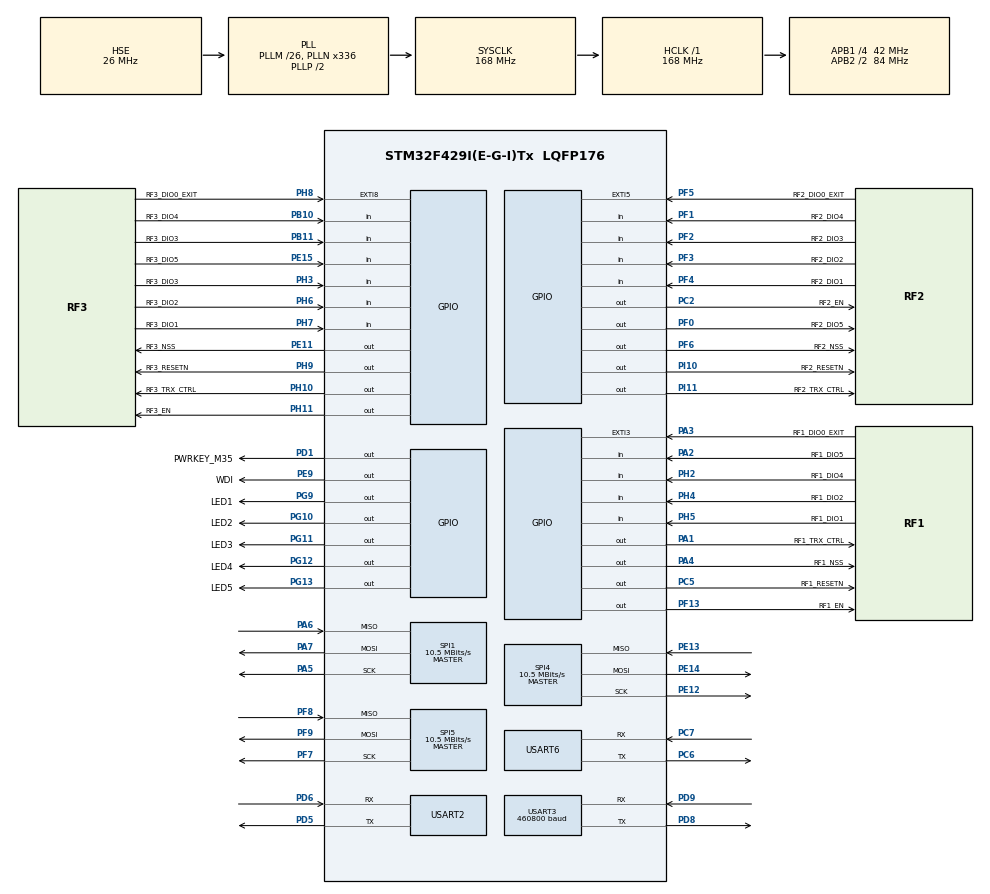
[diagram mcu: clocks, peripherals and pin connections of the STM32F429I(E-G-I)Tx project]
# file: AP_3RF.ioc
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Dma.Request0=USART3_RX
Dma.Request1=USART3_TX
Dma.Request2=USART6_RX
Dma.Request3=USART6_TX
Dma.Request4=USART2_RX
Dma.Request5=USART2_TX
Dma.USART2_RX.4.Direction=DMA_PERIPH_TO_MEMORY
Dma.USART2_RX.4.FIFOMode=DMA_FIFOMODE_DISABLE
Dma.USART2_RX.4.Instance=DMA1_Stream5
Dma.USART2_RX.4.MemDataAlignment=DMA_MDATAALIGN_BYTE
Dma.USART2_RX.4.MemInc=DMA_MINC_ENABLE
Dma.USART2_RX.4.Mode=DMA_NORMAL
Dma.USART2_RX.4.PeriphDataAlignment=DMA_PDATAALIGN_BYTE
Dma.USART2_RX.4.PeriphInc=DMA_PINC_DISABLE
Dma.USART2_RX.4.Priority=DMA_PRIORITY_MEDIUM
Dma.USART2_TX.5.Direction=DMA_MEMORY_TO_PERIPH
Dma.USART2_TX.5.FIFOMode=DMA_FIFOMODE_DISABLE
Dma.USART2_TX.5.Instance=DMA1_Stream6
Dma.USART2_TX.5.MemDataAlignment=DMA_MDATAALIGN_BYTE
Dma.USART2_TX.5.MemInc=DMA_MINC_ENABLE
Dma.USART2_TX.5.Mode=DMA_NORMAL
Dma.USART2_TX.5.PeriphDataAlignment=DMA_PDATAALIGN_BYTE
Dma.USART2_TX.5.PeriphInc=DMA_PINC_DISABLE
Dma.USART2_TX.5.Priority=DMA_PRIORITY_MEDIUM
Dma.USART3_RX.0.Direction=DMA_PERIPH_TO_MEMORY
Dma.USART3_RX.0.FIFOMode=DMA_FIFOMODE_DISABLE
Dma.USART3_RX.0.Instance=DMA1_Stream1
Dma.USART3_RX.0.MemDataAlignment=DMA_MDATAALIGN_BYTE
Dma.USART3_RX.0.MemInc=DMA_MINC_ENABLE
Dma.USART3_RX.0.Mode=DMA_NORMAL
Dma.USART3_RX.0.PeriphDataAlignment=DMA_PDATAALIGN_BYTE
Dma.USART3_RX.0.PeriphInc=DMA_PINC_DISABLE
Dma.USART3_RX.0.Priority=DMA_PRIORITY_HIGH
Dma.USART3_TX.1.Direction=DMA_MEMORY_TO_PERIPH
Dma.USART3_TX.1.FIFOMode=DMA_FIFOMODE_DISABLE
Dma.USART3_TX.1.Instance=DMA1_Stream3
Dma.USART3_TX.1.MemDataAlignment=DMA_MDATAALIGN_BYTE
Dma.USART3_TX.1.MemInc=DMA_MINC_ENABLE
Dma.USART3_TX.1.Mode=DMA_NORMAL
Dma.USART3_TX.1.PeriphDataAlignment=DMA_PDATAALIGN_BYTE
Dma.USART3_TX.1.PeriphInc=DMA_PINC_DISABLE
Dma.USART3_TX.1.Priority=DMA_PRIORITY_HIGH
Dma.USART6_RX.2.Direction=DMA_PERIPH_TO_MEMORY
Dma.USART6_RX.2.FIFOMode=DMA_FIFOMODE_DISABLE
Dma.USART6_RX.2.Instance=DMA2_Stream1
Dma.USART6_RX.2.MemDataAlignment=DMA_MDATAALIGN_BYTE
Dma.USART6_RX.2.MemInc=DMA_MINC_ENABLE
Dma.USART6_RX.2.Mode=DMA_NORMAL
Dma.USART6_RX.2.PeriphDataAlignment=DMA_PDATAALIGN_BYTE
Dma.USART6_RX.2.PeriphInc=DMA_PINC_DISABLE
Dma.USART6_RX.2.Priority=DMA_PRIORITY_LOW
Dma.USART6_TX.3.Direction=DMA_MEMORY_TO_PERIPH
Dma.USART6_TX.3.FIFOMode=DMA_FIFOMODE_DISABLE
Dma.USART6_TX.3.Instance=DMA2_Stream6
Dma.USART6_TX.3.MemDataAlignment=DMA_MDATAALIGN_BYTE
Dma.USART6_TX.3.MemInc=DMA_MINC_ENABLE
Dma.USART6_TX.3.Mode=DMA_NORMAL
Dma.USART6_TX.3.PeriphDataAlignment=DMA_PDATAALIGN_BYTE
Dma.USART6_TX.3.PeriphInc=DMA_PINC_DISABLE
Dma.USART6_TX.3.Priority=DMA_PRIORITY_LOW
Mcu.Family=STM32F4
Mcu.Name=STM32F429I(E-G-I)Tx
Mcu.Package=LQFP176
NVIC.DMA1_Stream1_IRQn=true\:3\:0\:true\:false\:true
NVIC.DMA1_Stream3_IRQn=true\:3\:0\:true\:false\:true
NVIC.DMA1_Stream5_IRQn=true\:3\:0\:true\:false\:true
NVIC.DMA1_Stream6_IRQn=true\:3\:0\:true\:false\:true
NVIC.DMA2_Stream1_IRQn=true\:3\:0\:true\:false\:true
NVIC.DMA2_Stream6_IRQn=true\:3\:0\:true\:false\:true
NVIC.EXTI3_IRQn=true\:1\:0\:true\:false\:true
NVIC.EXTI9_5_IRQn=true\:1\:0\:true\:false\:true
NVIC.PriorityGroup=NVIC_PRIORITYGROUP_4
NVIC.TIM1_UP_TIM10_IRQn=true\:0\:0\:false\:false\:true
NVIC.TimeBase=TIM1_UP_TIM10_IRQn
NVIC.TimeBaseIP=TIM10
NVIC.USART2_IRQn=true\:2\:0\:true\:false\:true
NVIC.USART3_IRQn=true\:1\:0\:true\:false\:true
NVIC.USART6_IRQn=true\:2\:0\:true\:false\:true
PA1.GPIO_Label=RF1_TRX_CTRL
PA1.GPIO_ModeDefaultOutputPP=GPIO_MODE_OUTPUT_OD
PA1.PinState=GPIO_PIN_SET
PA1.Signal=GPIO_Output
PA13.Mode=Serial_Wire
PA13.Signal=SYS_JTMS-SWDIO
PA14.Mode=Serial_Wire
PA14.Signal=SYS_JTCK-SWCLK
PA2.GPIO_Label=RF1_DIO5
PA2.Signal=GPIO_Input
PA3.GPIO_Label=RF1_DIO0_EXIT
PA3.GPIO_PuPd=GPIO_NOPULL
PA3.Signal=GPXTI3
PA4.GPIO_Label=RF1_NSS
PA4.GPIO_Speed=GPIO_SPEED_FREQ_VERY_HIGH
PA4.PinState=GPIO_PIN_SET
PA4.Signal=GPIO_Output
PA5.Mode=Full_Duplex_Master
PA5.Signal=SPI1_SCK
PA6.Mode=Full_Duplex_Master
PA6.Signal=SPI1_MISO
PA7.Mode=Full_Duplex_Master
PA7.Signal=SPI1_MOSI
PB10.GPIO_Label=RF3_DIO4
PB10.Signal=GPIO_Input
PB11.GPIO_Label=RF3_DIO3
PB11.Signal=GPIO_Input
PC2.GPIO_Label=RF2_EN
PC2.GPIO_Speed=GPIO_SPEED_FREQ_HIGH
PC2.PinState=GPIO_PIN_RESET
PC2.Signal=GPIO_Output
PC5.GPIO_Label=RF1_RESETN
PC5.GPIO_Speed=GPIO_SPEED_FREQ_VERY_HIGH
PC5.PinState=GPIO_PIN_SET
PC5.Signal=GPIO_Output
PC6.Mode=Asynchronous
PC6.Signal=USART6_TX
PC7.Mode=Asynchronous
PC7.Signal=USART6_RX
PD1.GPIO_Label=PWRKEY_M35
PD1.GPIO_Speed=GPIO_SPEED_FREQ_HIGH
PD1.PinState=GPIO_PIN_RESET
PD1.Signal=GPIO_Output
PD5.Mode=Asynchronous
PD5.Signal=USART2_TX
PD6.Mode=Asynchronous
PD6.Signal=USART2_RX
PD8.Mode=Asynchronous
PD8.Signal=USART3_TX
PD9.Mode=Asynchronous
PD9.Signal=USART3_RX
PE11.GPIO_Label=RF3_NSS
PE11.Signal=GPIO_Output
PE12.Mode=Full_Duplex_Master
PE12.Signal=SPI4_SCK
PE13.Mode=Full_Duplex_Master
PE13.Signal=SPI4_MISO
PE14.Mode=Full_Duplex_Master
PE14.Signal=SPI4_MOSI
PE15.GPIO_Label=RF3_DIO5
PE15.Signal=GPIO_Input
PE9.GPIO_Label=WDI
PE9.GPIO_Speed=GPIO_SPEED_FREQ_HIGH
PE9.Signal=GPIO_Output
PF0.GPIO_Label=RF2_DIO5
PF0.Signal=GPIO_Output
PF1.GPIO_Label=RF2_DIO4
PF1.Signal=GPIO_Input
PF13.GPIO_Label=RF1_EN
PF13.GPIO_Speed=GPIO_SPEED_FREQ_HIGH
PF13.PinState=GPIO_PIN_RESET
PF13.Signal=GPIO_Output
PF2.GPIO_Label=RF2_DIO3
PF2.Signal=GPIO_Input
PF3.GPIO_Label=RF2_DIO2
PF3.Signal=GPIO_Input
PF4.GPIO_Label=RF2_DIO1
PF4.Signal=GPIO_Input
PF5.GPIO_Label=RF2_DIO0_EXIT
PF5.GPIO_PuPd=GPIO_PULLUP
PF5.Signal=GPXTI5
PF6.GPIO_Label=RF2_NSS
PF6.Signal=GPIO_Output
PF7.Mode=Full_Duplex_Master
PF7.Signal=SPI5_SCK
PF8.Mode=Full_Duplex_Master
PF8.Signal=SPI5_MISO
PF9.Mode=Full_Duplex_Master
PF9.Signal=SPI5_MOSI
PG10.GPIO_Label=LED2
PG10.GPIO_ModeDefaultOutputPP=GPIO_MODE_OUTPUT_OD
PG10.GPIO_Speed=GPIO_SPEED_FREQ_VERY_HIGH
PG10.PinState=GPIO_PIN_SET
PG10.Signal=GPIO_Output
PG11.GPIO_Label=LED3
PG11.GPIO_ModeDefaultOutputPP=GPIO_MODE_OUTPUT_OD
PG11.GPIO_Speed=GPIO_SPEED_FREQ_VERY_HIGH
PG11.PinState=GPIO_PIN_SET
PG11.Signal=GPIO_Output
PG12.GPIO_Label=LED4
PG12.GPIO_ModeDefaultOutputPP=GPIO_MODE_OUTPUT_OD
PG12.GPIO_Speed=GPIO_SPEED_FREQ_VERY_HIGH
PG12.PinState=GPIO_PIN_SET
PG12.Signal=GPIO_Output
PG13.GPIO_Label=LED5
PG13.GPIO_ModeDefaultOutputPP=GPIO_MODE_OUTPUT_OD
PG13.GPIO_Speed=GPIO_SPEED_FREQ_VERY_HIGH
PG13.PinState=GPIO_PIN_SET
PG13.Signal=GPIO_Output
PG9.GPIO_Label=LED1
PG9.GPIO_ModeDefaultOutputPP=GPIO_MODE_OUTPUT_OD
PG9.GPIO_PuPd=GPIO_NOPULL
PG9.GPIO_Speed=GPIO_SPEED_FREQ_VERY_HIGH
PG9.PinState=GPIO_PIN_SET
PG9.Signal=GPIO_Output
PH0/OSC_IN.Mode=HSE-External-Clock-Source
PH0/OSC_IN.Signal=RCC_OSC_IN
PH1/OSC_OUT.Mode=HSE-External-Clock-Source
PH1/OSC_OUT.Signal=RCC_OSC_OUT
PH10.GPIO_Label=RF3_TRX_CTRL
PH10.GPIO_ModeDefaultOutputPP=GPIO_MODE_OUTPUT_OD
PH10.GPIO_Speed=GPIO_SPEED_FREQ_VERY_HIGH
PH10.PinState=GPIO_PIN_SET
PH10.Signal=GPIO_Output
PH11.GPIO_Label=RF3_EN
PH11.GPIO_Speed=GPIO_SPEED_FREQ_VERY_HIGH
PH11.Signal=GPIO_Output
PH2.GPIO_Label=RF1_DIO4
PH2.Signal=GPIO_Input
PH3.GPIO_Label=RF3_DIO3
PH3.Signal=GPIO_Input
PH4.GPIO_Label=RF1_DIO2
PH4.Signal=GPIO_Input
PH5.GPIO_Label=RF1_DIO1
PH5.Signal=GPIO_Input
PH6.GPIO_Label=RF3_DIO2
PH6.Signal=GPIO_Input
PH7.GPIO_Label=RF3_DIO1
PH7.Signal=GPIO_Input
PH8.GPIO_Label=RF3_DIO0_EXIT
PH8.GPIO_PuPd=GPIO_PULLUP
PH8.Signal=GPXTI8
PH9.GPIO_Label=RF3_RESETN
PH9.GPIO_ModeDefaultOutputPP=GPIO_MODE_OUTPUT_OD
PH9.GPIO_Speed=GPIO_SPEED_FREQ_VERY_HIGH
PH9.PinState=GPIO_PIN_SET
PH9.Signal=GPIO_Output
PI10.GPIO_Label=RF2_RESETN
PI10.GPIO_ModeDefaultOutputPP=GPIO_MODE_OUTPUT_OD
PI10.GPIO_Speed=GPIO_SPEED_FREQ_VERY_HIGH
PI10.PinState=GPIO_PIN_SET
PI10.Signal=GPIO_Output
PI11.GPIO_Label=RF2_TRX_CTRL
PI11.GPIO_ModeDefaultOutputPP=GPIO_MODE_OUTPUT_OD
PI11.GPIO_Speed=GPIO_SPEED_FREQ_VERY_HIGH
PI11.PinState=GPIO_PIN_SET
PI11.Signal=GPIO_Output
ProjectManager.HeapSize=0x200
ProjectManager.StackSize=0x400
ProjectManager.TargetToolchain=MDK-ARM V5
RCC.48MHZClocksFreq_Value=84000000
RCC.AHBFreq_Value=168000000
RCC.APB1CLKDivider=RCC_HCLK_DIV4
RCC.APB1Freq_Value=42000000
RCC.APB1TimFreq_Value=84000000
RCC.APB2CLKDivider=RCC_HCLK_DIV2
RCC.APB2Freq_Value=84000000
RCC.APB2TimFreq_Value=168000000
RCC.CortexFreq_Value=168000000
RCC.HCLKFreq_Value=168000000
RCC.HSE_VALUE=26000000
RCC.HSI_VALUE=16000000
RCC.LSE_VALUE=32768
RCC.PLLM=26
RCC.PLLN=336
RCC.PLLSourceVirtual=RCC_PLLSOURCE_HSE
RCC.SYSCLKFreq_VALUE=168000000
RCC.SYSCLKSource=RCC_SYSCLKSOURCE_PLLCLK
RCC.VCOOutputFreq_Value=336000000
SPI1.BaudRatePrescaler=SPI_BAUDRATEPRESCALER_8
SPI1.CalculateBaudRate=10.5 MBits/s
SPI1.Direction=SPI_DIRECTION_2LINES
SPI1.Mode=SPI_MODE_MASTER
SPI1.VirtualType=VM_MASTER
SPI4.BaudRatePrescaler=SPI_BAUDRATEPRESCALER_8
SPI4.CalculateBaudRate=10.5 MBits/s
SPI4.Direction=SPI_DIRECTION_2LINES
SPI4.Mode=SPI_MODE_MASTER
SPI4.VirtualType=VM_MASTER
SPI5.BaudRatePrescaler=SPI_BAUDRATEPRESCALER_8
SPI5.CalculateBaudRate=10.5 MBits/s
SPI5.Direction=SPI_DIRECTION_2LINES
SPI5.Mode=SPI_MODE_MASTER
SPI5.VirtualType=VM_MASTER
USART2.VirtualMode=VM_ASYNC
USART3.BaudRate=460800
USART3.VirtualMode=VM_ASYNC
USART6.VirtualMode=VM_ASYNC
VP_CRC_VS_CRC.Mode=CRC_Activate
VP_SYS_VS_tim10.Mode=TIM10
board=AP_3RF

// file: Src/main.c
/**
  ******************************************************************************
  * File Name          : main.c
  * Description        : Main program body
  ******************************************************************************
  ** This notice applies to any and all portions of this file
  * that are not between comment pairs USER CODE BEGIN and
  * USER CODE END. Other portions of this file, whether
  * inserted by the user or by software development tools
  * are owned by their respective copyright owners.
  *
  * COPYRIGHT(c) 2018 STMicroelectronics
  *
  * Redistribution and use in source and binary forms, with or without modification,
  * are permitted provided that the following conditions are met:
  *   1. Redistributions of source code must retain the above copyright notice,
  *      this list of conditions and the following disclaimer.
  *   2. Redistributions in binary form must reproduce the above copyright notice,
  *      this list of conditions and the following disclaimer in the documentation
  *      and/or other materials provided with the distribution.
  *   3. Neither the name of STMicroelectronics nor the names of its contributors
  *      may be used to endorse or promote products derived from this software
  *      without specific prior written permission.
  *
  * THIS SOFTWARE IS PROVIDED BY THE COPYRIGHT HOLDERS AND CONTRIBUTORS "AS IS"
  * AND ANY EXPRESS OR IMPLIED WARRANTIES, INCLUDING, BUT NOT LIMITED TO, THE
  * IMPLIED WARRANTIES OF MERCHANTABILITY AND FITNESS FOR A PARTICULAR PURPOSE ARE
  * DISCLAIMED. IN NO EVENT SHALL THE COPYRIGHT HOLDER OR CONTRIBUTORS BE LIABLE
  * FOR ANY DIRECT, INDIRECT, INCIDENTAL, SPECIAL, EXEMPLARY, OR CONSEQUENTIAL
  * DAMAGES (INCLUDING, BUT NOT LIMITED TO, PROCUREMENT OF SUBSTITUTE GOODS OR
  * SERVICES; LOSS OF USE, DATA, OR PROFITS; OR BUSINESS INTERRUPTION) HOWEVER
  * CAUSED AND ON ANY THEORY OF LIABILITY, WHETHER IN CONTRACT, STRICT LIABILITY,
  * OR TORT (INCLUDING NEGLIGENCE OR OTHERWISE) ARISING IN ANY WAY OUT OF THE USE
  * OF THIS SOFTWARE, EVEN IF ADVISED OF THE POSSIBILITY OF SUCH DAMAGE.
  *
  ******************************************************************************
  */
#include "main.h"
#include "stm32f4xx_hal.h"

/* USER CODE BEGIN Includes */
#include "rf.h"
#include "debug_uart.h"
#include "ap_s.h"
#include "flash.h"
/* USER CODE END Includes */

CRC_HandleTypeDef hcrc;

SPI_HandleTypeDef hspi1;
SPI_HandleTypeDef hspi4;
SPI_HandleTypeDef hspi5;

UART_HandleTypeDef huart2;
UART_HandleTypeDef huart3;
UART_HandleTypeDef huart6;
DMA_HandleTypeDef hdma_usart2_rx;
DMA_HandleTypeDef hdma_usart2_tx;
DMA_HandleTypeDef hdma_usart3_rx;
DMA_HandleTypeDef hdma_usart3_tx;
DMA_HandleTypeDef hdma_usart6_rx;
DMA_HandleTypeDef hdma_usart6_tx;

/* USER CODE BEGIN PV */
/* Private variables ---------------------------------------------------------*/

/* USER CODE END PV */

void SystemClock_Config(void);
static void MX_GPIO_Init(void);
static void MX_DMA_Init(void);
static void MX_CRC_Init(void);
static void MX_SPI1_Init(void);
static void MX_SPI4_Init(void);
static void MX_SPI5_Init(void);
static void MX_USART2_UART_Init(void);
static void MX_USART3_UART_Init(void);
static void MX_USART6_UART_Init(void);

/* USER CODE BEGIN PFP */
/* Private function prototypes -----------------------------------------------*/

/* USER CODE END PFP */

/* USER CODE BEGIN 0 */
extern void power_on_auto_send_test();
int enable_send_sensor_rftest = 0;

void watch_dog_feed(void)
{
	HAL_GPIO_TogglePin(WDI_GPIO_Port,WDI_Pin);

}

/* USER CODE END 0 */

int main(void)
{

  /* MCU Configuration----------------------------------------------------------*/

  /* Reset of all peripherals, Initializes the Flash interface and the Systick. */
  HAL_Init();

  /* Configure the system clock */
  SystemClock_Config();

  /* Initialize all configured peripherals */
  MX_GPIO_Init();
  MX_DMA_Init();
  MX_CRC_Init();
  MX_SPI1_Init();
  MX_SPI4_Init();
  MX_SPI5_Init();
  MX_USART2_UART_Init();
  MX_USART3_UART_Init();
  MX_USART6_UART_Init();

  /* USER CODE BEGIN 2 */
	help(0);
	init_ap_param();
	read_ap_param_flash();
	//default_1000p_test();

	RF_init();
	start_from_debug_dma_receive();
	HAL_SYSTICK_Config(840820);

	power_on_auto_send_test();
  /* USER CODE END 2 */

  /* Infinite loop */
  /* USER CODE BEGIN WHILE */
  while (1)
  {

		watch_dog_feed();
		HAL_GPIO_TogglePin(LED1_GPIO_Port,LED1_Pin);
  /* USER CODE END WHILE */

  /* USER CODE BEGIN 3 */
		debug_cmd_handle();
		test_1000packet_send();
		debug_send_double_buff_poll();

		if(enable_send_sensor_rftest)
			send_sensor_rftest_packet();

		if(ap_param_write_flash_flag)
			write_ap_param_flash();

		debug_rf_send_syn_ok();

  }
  /* USER CODE END 3 */

}

/** System Clock Configuration
*/
void SystemClock_Config(void)
{

  RCC_OscInitTypeDef RCC_OscInitStruct;
  RCC_ClkInitTypeDef RCC_ClkInitStruct;

    /**Configure the main internal regulator output voltage
    */
  __HAL_RCC_PWR_CLK_ENABLE();

  __HAL_PWR_VOLTAGESCALING_CONFIG(PWR_REGULATOR_VOLTAGE_SCALE1);

    /**Initializes the CPU, AHB and APB busses clocks
    */
  RCC_OscInitStruct.OscillatorType = RCC_OSCILLATORTYPE_HSE;
  RCC_OscInitStruct.HSEState = RCC_HSE_BYPASS;
  RCC_OscInitStruct.PLL.PLLState = RCC_PLL_ON;
  RCC_OscInitStruct.PLL.PLLSource = RCC_PLLSOURCE_HSE;
  RCC_OscInitStruct.PLL.PLLM = 26;
  RCC_OscInitStruct.PLL.PLLN = 336;
  RCC_OscInitStruct.PLL.PLLP = RCC_PLLP_DIV2;
  RCC_OscInitStruct.PLL.PLLQ = 4;
  if (HAL_RCC_OscConfig(&RCC_OscInitStruct) != HAL_OK)
  {
    _Error_Handler(__FILE__, __LINE__);
  }

    /**Initializes the CPU, AHB and APB busses clocks
    */
  RCC_ClkInitStruct.ClockType = RCC_CLOCKTYPE_HCLK|RCC_CLOCKTYPE_SYSCLK
                              |RCC_CLOCKTYPE_PCLK1|RCC_CLOCKTYPE_PCLK2;
  RCC_ClkInitStruct.SYSCLKSource = RCC_SYSCLKSOURCE_PLLCLK;
  RCC_ClkInitStruct.AHBCLKDivider = RCC_SYSCLK_DIV1;
  RCC_ClkInitStruct.APB1CLKDivider = RCC_HCLK_DIV4;
  RCC_ClkInitStruct.APB2CLKDivider = RCC_HCLK_DIV2;

  if (HAL_RCC_ClockConfig(&RCC_ClkInitStruct, FLASH_LATENCY_5) != HAL_OK)
  {
    _Error_Handler(__FILE__, __LINE__);
  }

    /**Configure the Systick interrupt time
    */
  HAL_SYSTICK_Config(HAL_RCC_GetHCLKFreq()/1000);

    /**Configure the Systick
    */
  HAL_SYSTICK_CLKSourceConfig(SYSTICK_CLKSOURCE_HCLK);

  /* SysTick_IRQn interrupt configuration */
  HAL_NVIC_SetPriority(SysTick_IRQn, 0, 0);
}

/* CRC init function */
static void MX_CRC_Init(void)
{

  hcrc.Instance = CRC;
  if (HAL_CRC_Init(&hcrc) != HAL_OK)
  {
    _Error_Handler(__FILE__, __LINE__);
  }

}

/* SPI1 init function */
static void MX_SPI1_Init(void)
{

  hspi1.Instance = SPI1;
  hspi1.Init.Mode = SPI_MODE_MASTER;
  hspi1.Init.Direction = SPI_DIRECTION_2LINES;
  hspi1.Init.DataSize = SPI_DATASIZE_8BIT;
  hspi1.Init.CLKPolarity = SPI_POLARITY_LOW;
  hspi1.Init.CLKPhase = SPI_PHASE_1EDGE;
  hspi1.Init.NSS = SPI_NSS_SOFT;
  hspi1.Init.BaudRatePrescaler = SPI_BAUDRATEPRESCALER_16;
  hspi1.Init.FirstBit = SPI_FIRSTBIT_MSB;
  hspi1.Init.TIMode = SPI_TIMODE_DISABLE;
  hspi1.Init.CRCCalculation = SPI_CRCCALCULATION_DISABLE;
  hspi1.Init.CRCPolynomial = 10;
  if (HAL_SPI_Init(&hspi1) != HAL_OK)
  {
    _Error_Handler(__FILE__, __LINE__);
  }

}

/* SPI4 init function */
static void MX_SPI4_Init(void)
{

  hspi4.Instance = SPI4;
  hspi4.Init.Mode = SPI_MODE_MASTER;
  hspi4.Init.Direction = SPI_DIRECTION_2LINES;
  hspi4.Init.DataSize = SPI_DATASIZE_8BIT;
  hspi4.Init.CLKPolarity = SPI_POLARITY_LOW;
  hspi4.Init.CLKPhase = SPI_PHASE_1EDGE;
  hspi4.Init.NSS = SPI_NSS_SOFT;
  hspi4.Init.BaudRatePrescaler = SPI_BAUDRATEPRESCALER_8;
  hspi4.Init.FirstBit = SPI_FIRSTBIT_MSB;
  hspi4.Init.TIMode = SPI_TIMODE_DISABLE;
  hspi4.Init.CRCCalculation = SPI_CRCCALCULATION_DISABLE;
  hspi4.Init.CRCPolynomial = 10;
  if (HAL_SPI_Init(&hspi4) != HAL_OK)
  {
    _Error_Handler(__FILE__, __LINE__);
  }

}

/* SPI5 init function */
static void MX_SPI5_Init(void)
{

  hspi5.Instance = SPI5;
  hspi5.Init.Mode = SPI_MODE_MASTER;
  hspi5.Init.Direction = SPI_DIRECTION_2LINES;
  hspi5.Init.DataSize = SPI_DATASIZE_8BIT;
  hspi5.Init.CLKPolarity = SPI_POLARITY_LOW;
  hspi5.Init.CLKPhase = SPI_PHASE_1EDGE;
  hspi5.Init.NSS = SPI_NSS_SOFT;
  hspi5.Init.BaudRatePrescaler = SPI_BAUDRATEPRESCALER_8;
  hspi5.Init.FirstBit = SPI_FIRSTBIT_MSB;
  hspi5.Init.TIMode = SPI_TIMODE_DISABLE;
  hspi5.Init.CRCCalculation = SPI_CRCCALCULATION_DISABLE;
  hspi5.Init.CRCPolynomial = 10;
  if (HAL_SPI_Init(&hspi5) != HAL_OK)
  {
    _Error_Handler(__FILE__, __LINE__);
  }

}

/* USART2 init function */
static void MX_USART2_UART_Init(void)
{

  huart2.Instance = USART2;
  huart2.Init.BaudRate = 115200;
  huart2.Init.WordLength = UART_WORDLENGTH_8B;
  huart2.Init.StopBits = UART_STOPBITS_1;
  huart2.Init.Parity = UART_PARITY_NONE;
  huart2.Init.Mode = UART_MODE_TX_RX;
  huart2.Init.HwFlowCtl = UART_HWCONTROL_NONE;
  huart2.Init.OverSampling = UART_OVERSAMPLING_16;
  if (HAL_UART_Init(&huart2) != HAL_OK)
  {
    _Error_Handler(__FILE__, __LINE__);
  }

}

/* USART3 init function */
static void MX_USART3_UART_Init(void)
{

  huart3.Instance = USART3;
  huart3.Init.BaudRate = 460800;
  huart3.Init.WordLength = UART_WORDLENGTH_8B;
  huart3.Init.StopBits = UART_STOPBITS_1;
  huart3.Init.Parity = UART_PARITY_NONE;
  huart3.Init.Mode = UART_MODE_TX_RX;
  huart3.Init.HwFlowCtl = UART_HWCONTROL_NONE;
  huart3.Init.OverSampling = UART_OVERSAMPLING_16;
  if (HAL_UART_Init(&huart3) != HAL_OK)
  {
    _Error_Handler(__FILE__, __LINE__);
  }

}

/* USART6 init function */
static void MX_USART6_UART_Init(void)
{

  huart6.Instance = USART6;
  huart6.Init.BaudRate = 115200;
  huart6.Init.WordLength = UART_WORDLENGTH_8B;
  huart6.Init.StopBits = UART_STOPBITS_1;
  huart6.Init.Parity = UART_PARITY_NONE;
  huart6.Init.Mode = UART_MODE_TX_RX;
  huart6.Init.HwFlowCtl = UART_HWCONTROL_NONE;
  huart6.Init.OverSampling = UART_OVERSAMPLING_16;
  if (HAL_UART_Init(&huart6) != HAL_OK)
  {
    _Error_Handler(__FILE__, __LINE__);
  }

}

static void MX_DMA_Init(void)
{
  /* DMA controller clock enable */
  __HAL_RCC_DMA1_CLK_ENABLE();
  __HAL_RCC_DMA2_CLK_ENABLE();

  /* DMA interrupt init */
  /* DMA1_Stream1_IRQn interrupt configuration */
  HAL_NVIC_SetPriority(DMA1_Stream1_IRQn, 3, 0);
  HAL_NVIC_EnableIRQ(DMA1_Stream1_IRQn);
  /* DMA1_Stream3_IRQn interrupt configuration */
  HAL_NVIC_SetPriority(DMA1_Stream3_IRQn, 3, 0);
  HAL_NVIC_EnableIRQ(DMA1_Stream3_IRQn);
  /* DMA1_Stream5_IRQn interrupt configuration */
  HAL_NVIC_SetPriority(DMA1_Stream5_IRQn, 3, 0);
  HAL_NVIC_EnableIRQ(DMA1_Stream5_IRQn);
  /* DMA1_Stream6_IRQn interrupt configuration */
  HAL_NVIC_SetPriority(DMA1_Stream6_IRQn, 3, 0);
  HAL_NVIC_EnableIRQ(DMA1_Stream6_IRQn);
  /* DMA2_Stream1_IRQn interrupt configuration */
  HAL_NVIC_SetPriority(DMA2_Stream1_IRQn, 3, 0);
  HAL_NVIC_EnableIRQ(DMA2_Stream1_IRQn);
  /* DMA2_Stream6_IRQn interrupt configuration */
  HAL_NVIC_SetPriority(DMA2_Stream6_IRQn, 3, 0);
  HAL_NVIC_EnableIRQ(DMA2_Stream6_IRQn);

}

/** Configure pins as
        * Analog
        * Input
        * Output
        * EVENT_OUT
        * EXTI
*/
static void MX_GPIO_Init(void)
{

  GPIO_InitTypeDef GPIO_InitStruct;

  /* GPIO Ports Clock Enable */
  __HAL_RCC_GPIOI_CLK_ENABLE();
  __HAL_RCC_GPIOF_CLK_ENABLE();
  __HAL_RCC_GPIOH_CLK_ENABLE();
  __HAL_RCC_GPIOC_CLK_ENABLE();
  __HAL_RCC_GPIOA_CLK_ENABLE();
  __HAL_RCC_GPIOE_CLK_ENABLE();
  __HAL_RCC_GPIOB_CLK_ENABLE();
  __HAL_RCC_GPIOD_CLK_ENABLE();
  __HAL_RCC_GPIOG_CLK_ENABLE();

  /*Configure GPIO pin Output Level */
  HAL_GPIO_WritePin(GPIOI, RF2_RESETN_Pin|RF2_TRX_CTRL_Pin, GPIO_PIN_SET);

  /*Configure GPIO pin Output Level */
  HAL_GPIO_WritePin(GPIOF, RF2_DIO5_Pin|RF2_NSS_Pin, GPIO_PIN_RESET);

  /*Configure GPIO pin Output Level */
  HAL_GPIO_WritePin(RF2_EN_GPIO_Port, RF2_EN_Pin, GPIO_PIN_RESET);

  /*Configure GPIO pin Output Level */
  HAL_GPIO_WritePin(GPIOA, RF1_TRX_CTRL_Pin|RF1_NSS_Pin, GPIO_PIN_SET);

  /*Configure GPIO pin Output Level */
  HAL_GPIO_WritePin(RF1_RESETN_GPIO_Port, RF1_RESETN_Pin, GPIO_PIN_SET);

  /*Configure GPIO pin Output Level */
  HAL_GPIO_WritePin(RF1_EN_GPIO_Port, RF1_EN_Pin, GPIO_PIN_SET);

  /*Configure GPIO pin Output Level */
  HAL_GPIO_WritePin(GPIOE, WDI_Pin|RF3_NSS_Pin, GPIO_PIN_RESET);

  /*Configure GPIO pin Output Level */
  HAL_GPIO_WritePin(GPIOH, RF3_RESETN_Pin|RF3_TRX_CTRL_Pin, GPIO_PIN_SET);

  /*Configure GPIO pin Output Level */
  HAL_GPIO_WritePin(RF3_EN_GPIO_Port, RF3_EN_Pin, GPIO_PIN_RESET);

  /*Configure GPIO pin Output Level */
  HAL_GPIO_WritePin(PWRKEY_M35_GPIO_Port, PWRKEY_M35_Pin, GPIO_PIN_RESET);

  /*Configure GPIO pin Output Level */
  HAL_GPIO_WritePin(GPIOG, LED1_Pin|LED2_Pin|LED3_Pin|LED4_Pin
                          |LED5_Pin, GPIO_PIN_SET);

  /*Configure GPIO pins : RF2_RESETN_Pin RF2_TRX_CTRL_Pin */
  GPIO_InitStruct.Pin = RF2_RESETN_Pin|RF2_TRX_CTRL_Pin;
  GPIO_InitStruct.Mode = GPIO_MODE_OUTPUT_PP;
  GPIO_InitStruct.Pull = GPIO_NOPULL;
  GPIO_InitStruct.Speed = GPIO_SPEED_FREQ_VERY_HIGH;
  HAL_GPIO_Init(GPIOI, &GPIO_InitStruct);

  /*Configure GPIO pins : RF2_DIO5_Pin RF2_NSS_Pin */
  GPIO_InitStruct.Pin = RF2_DIO5_Pin|RF2_NSS_Pin;
  GPIO_InitStruct.Mode = GPIO_MODE_OUTPUT_PP;
  GPIO_InitStruct.Pull = GPIO_NOPULL;
  GPIO_InitStruct.Speed = GPIO_SPEED_FREQ_LOW;
  HAL_GPIO_Init(GPIOF, &GPIO_InitStruct);

  /*Configure GPIO pins : RF2_DIO4_Pin RF2_DIO3_Pin RF2_DIO2_Pin RF2_DIO1_Pin */
  GPIO_InitStruct.Pin = RF2_DIO4_Pin|RF2_DIO3_Pin|RF2_DIO2_Pin|RF2_DIO1_Pin;
  GPIO_InitStruct.Mode = GPIO_MODE_INPUT;
  GPIO_InitStruct.Pull = GPIO_NOPULL;
  HAL_GPIO_Init(GPIOF, &GPIO_InitStruct);

  /*Configure GPIO pin : RF2_DIO0_EXIT_Pin */
  GPIO_InitStruct.Pin = RF2_DIO0_EXIT_Pin;
  GPIO_InitStruct.Mode = GPIO_MODE_IT_RISING;
  GPIO_InitStruct.Pull = GPIO_PULLUP;
  HAL_GPIO_Init(RF2_DIO0_EXIT_GPIO_Port, &GPIO_InitStruct);

  /*Configure GPIO pin : RF2_EN_Pin */
  GPIO_InitStruct.Pin = RF2_EN_Pin;
  GPIO_InitStruct.Mode = GPIO_MODE_OUTPUT_PP;
  GPIO_InitStruct.Pull = GPIO_NOPULL;
  GPIO_InitStruct.Speed = GPIO_SPEED_FREQ_HIGH;
  HAL_GPIO_Init(RF2_EN_GPIO_Port, &GPIO_InitStruct);

  /*Configure GPIO pin : RF1_TRX_CTRL_Pin */
  GPIO_InitStruct.Pin = RF1_TRX_CTRL_Pin;
  GPIO_InitStruct.Mode = GPIO_MODE_OUTPUT_PP;
  GPIO_InitStruct.Pull = GPIO_NOPULL;
  GPIO_InitStruct.Speed = GPIO_SPEED_FREQ_LOW;
  HAL_GPIO_Init(RF1_TRX_CTRL_GPIO_Port, &GPIO_InitStruct);

  /*Configure GPIO pin : RF1_DIO5_Pin */
  GPIO_InitStruct.Pin = RF1_DIO5_Pin;
  GPIO_InitStruct.Mode = GPIO_MODE_INPUT;
  GPIO_InitStruct.Pull = GPIO_NOPULL;
  HAL_GPIO_Init(RF1_DIO5_GPIO_Port, &GPIO_InitStruct);

  /*Configure GPIO pins : RF1_DIO4_Pin RF_DIO3_Pin RF1_DIO2_Pin RF1_DIO1_Pin
                           RF3_DIO2_Pin RF3_DIO1_Pin */
  GPIO_InitStruct.Pin = RF1_DIO4_Pin|RF_DIO3_Pin|RF1_DIO2_Pin|RF1_DIO1_Pin
                          |RF3_DIO2_Pin|RF3_DIO1_Pin;
  GPIO_InitStruct.Mode = GPIO_MODE_INPUT;
  GPIO_InitStruct.Pull = GPIO_NOPULL;
  HAL_GPIO_Init(GPIOH, &GPIO_InitStruct);

  /*Configure GPIO pin : RF1_DIO0_EXIT_Pin */
  GPIO_InitStruct.Pin = RF1_DIO0_EXIT_Pin;
  GPIO_InitStruct.Mode = GPIO_MODE_IT_RISING;
  GPIO_InitStruct.Pull = GPIO_NOPULL;
  HAL_GPIO_Init(RF1_DIO0_EXIT_GPIO_Port, &GPIO_InitStruct);

  /*Configure GPIO pin : RF1_NSS_Pin */
  GPIO_InitStruct.Pin = RF1_NSS_Pin;
  GPIO_InitStruct.Mode = GPIO_MODE_OUTPUT_PP;
  GPIO_InitStruct.Pull = GPIO_NOPULL;
  GPIO_InitStruct.Speed = GPIO_SPEED_FREQ_VERY_HIGH;
  HAL_GPIO_Init(RF1_NSS_GPIO_Port, &GPIO_InitStruct);

  /*Configure GPIO pin : RF1_RESETN_Pin */
  GPIO_InitStruct.Pin = RF1_RESETN_Pin;
  GPIO_InitStruct.Mode = GPIO_MODE_OUTPUT_PP;
  GPIO_InitStruct.Pull = GPIO_NOPULL;
  GPIO_InitStruct.Speed = GPIO_SPEED_FREQ_VERY_HIGH;
  HAL_GPIO_Init(RF1_RESETN_GPIO_Port, &GPIO_InitStruct);

  /*Configure GPIO pin : RF1_EN_Pin */
  GPIO_InitStruct.Pin = RF1_EN_Pin;
  GPIO_InitStruct.Mode = GPIO_MODE_OUTPUT_PP;
  GPIO_InitStruct.Pull = GPIO_NOPULL;
  GPIO_InitStruct.Speed = GPIO_SPEED_FREQ_HIGH;
  HAL_GPIO_Init(RF1_EN_GPIO_Port, &GPIO_InitStruct);

  /*Configure GPIO pin : WDI_Pin */
  GPIO_InitStruct.Pin = WDI_Pin;
  GPIO_InitStruct.Mode = GPIO_MODE_OUTPUT_PP;
  GPIO_InitStruct.Pull = GPIO_NOPULL;
  GPIO_InitStruct.Speed = GPIO_SPEED_FREQ_HIGH;
  HAL_GPIO_Init(WDI_GPIO_Port, &GPIO_InitStruct);

  /*Configure GPIO pin : RF3_NSS_Pin */
  GPIO_InitStruct.Pin = RF3_NSS_Pin;
  GPIO_InitStruct.Mode = GPIO_MODE_OUTPUT_PP;
  GPIO_InitStruct.Pull = GPIO_NOPULL;
  GPIO_InitStruct.Speed = GPIO_SPEED_FREQ_LOW;
  HAL_GPIO_Init(RF3_NSS_GPIO_Port, &GPIO_InitStruct);

  /*Configure GPIO pin : RF3_DIO5_Pin */
  GPIO_InitStruct.Pin = RF3_DIO5_Pin;
  GPIO_InitStruct.Mode = GPIO_MODE_INPUT;
  GPIO_InitStruct.Pull = GPIO_NOPULL;
  HAL_GPIO_Init(RF3_DIO5_GPIO_Port, &GPIO_InitStruct);

  /*Configure GPIO pins : RF3_DIO4_Pin RF3_DIO3_Pin */
  GPIO_InitStruct.Pin = RF3_DIO4_Pin|RF3_DIO3_Pin;
  GPIO_InitStruct.Mode = GPIO_MODE_INPUT;
  GPIO_InitStruct.Pull = GPIO_NOPULL;
  HAL_GPIO_Init(GPIOB, &GPIO_InitStruct);

  /*Configure GPIO pin : RF3_DIO0_EXIT_Pin */
  GPIO_InitStruct.Pin = RF3_DIO0_EXIT_Pin;
  GPIO_InitStruct.Mode = GPIO_MODE_IT_RISING;
  GPIO_InitStruct.Pull = GPIO_PULLUP;
  HAL_GPIO_Init(RF3_DIO0_EXIT_GPIO_Port, &GPIO_InitStruct);

  /*Configure GPIO pins : RF3_RESETN_Pin RF3_TRX_CTRL_Pin */
  GPIO_InitStruct.Pin = RF3_RESETN_Pin|RF3_TRX_CTRL_Pin;
  GPIO_InitStruct.Mode = GPIO_MODE_OUTPUT_PP;
  GPIO_InitStruct.Pull = GPIO_NOPULL;
  GPIO_InitStruct.Speed = GPIO_SPEED_FREQ_VERY_HIGH;
  HAL_GPIO_Init(GPIOH, &GPIO_InitStruct);

  /*Configure GPIO pin : RF3_EN_Pin */
  GPIO_InitStruct.Pin = RF3_EN_Pin;
  GPIO_InitStruct.Mode = GPIO_MODE_OUTPUT_PP;
  GPIO_InitStruct.Pull = GPIO_NOPULL;
  GPIO_InitStruct.Speed = GPIO_SPEED_FREQ_VERY_HIGH;
  HAL_GPIO_Init(RF3_EN_GPIO_Port, &GPIO_InitStruct);

  /*Configure GPIO pin : PWRKEY_M35_Pin */
  GPIO_InitStruct.Pin = PWRKEY_M35_Pin;
  GPIO_InitStruct.Mode = GPIO_MODE_OUTPUT_PP;
  GPIO_InitStruct.Pull = GPIO_NOPULL;
  GPIO_InitStruct.Speed = GPIO_SPEED_FREQ_HIGH;
  HAL_GPIO_Init(PWRKEY_M35_GPIO_Port, &GPIO_InitStruct);

  /*Configure GPIO pins : LED1_Pin LED2_Pin LED3_Pin LED4_Pin
                           LED5_Pin */
  GPIO_InitStruct.Pin = LED1_Pin|LED2_Pin|LED3_Pin|LED4_Pin
                          |LED5_Pin;
  GPIO_InitStruct.Mode = GPIO_MODE_OUTPUT_OD;
  GPIO_InitStruct.Pull = GPIO_NOPULL;
  GPIO_InitStruct.Speed = GPIO_SPEED_FREQ_VERY_HIGH;
  HAL_GPIO_Init(GPIOG, &GPIO_InitStruct);

  /* EXTI interrupt init*/
  HAL_NVIC_SetPriority(EXTI3_IRQn, 1, 0);
  HAL_NVIC_EnableIRQ(EXTI3_IRQn);

  HAL_NVIC_SetPriority(EXTI9_5_IRQn, 1, 0);
  HAL_NVIC_EnableIRQ(EXTI9_5_IRQn);

}

void HAL_TIM_PeriodElapsedCallback(TIM_HandleTypeDef *htim)
{
  if (htim->Instance == TIM10) {
    HAL_IncTick();
  }
}

void _Error_Handler(char * file, int line)
{
  while(1)
  {
  }
}

/************************ (C) COPYRIGHT STMicroelectronics *****END OF FILE****/
